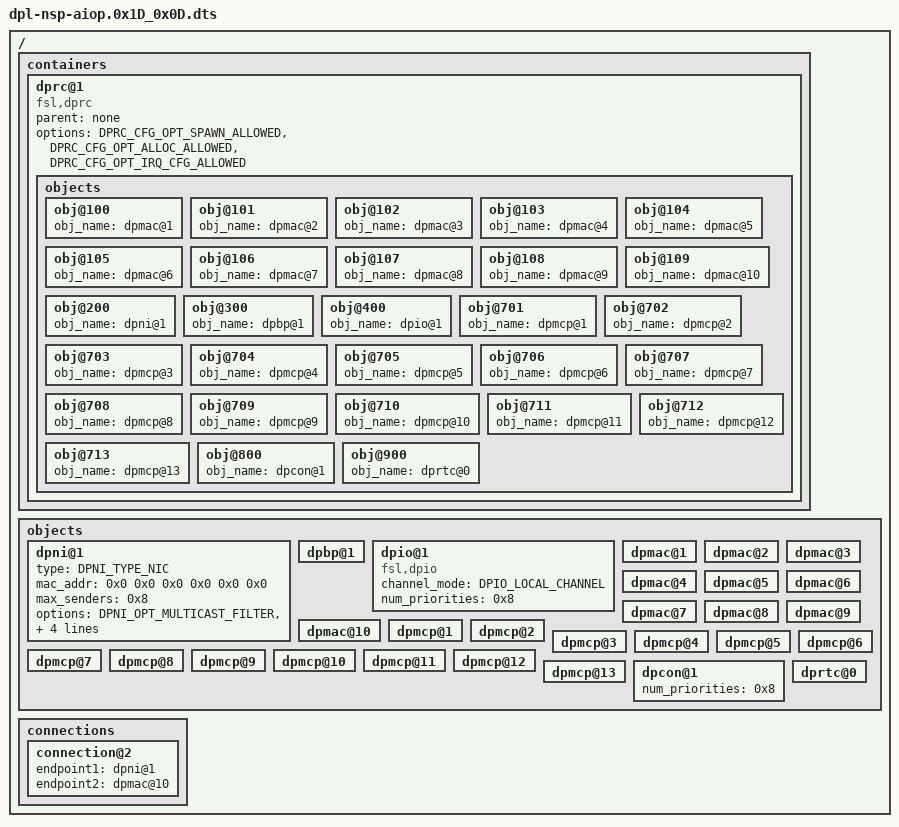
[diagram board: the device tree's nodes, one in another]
/*
 * Copyright 2017 NXP
 *
 * Redistribution and use in source and binary forms, with or without
 * modification, are permitted provided that the following conditions are met:
 *   * Redistributions of source code must retain the above copyright
 *     notice, this list of conditions and the following disclaimer.
 *   * Redistributions in binary form must reproduce the above copyright
 *     notice, this list of conditions and the following disclaimer in the
 *     documentation and/or other materials provided with the distribution.
 *   * Neither the name of the above-listed copyright holders nor the
 *     names of any contributors may be used to endorse or promote products
 *     derived from this software without specific prior written permission.
 *
 * THIS SOFTWARE IS PROVIDED BY THE COPYRIGHT HOLDERS AND CONTRIBUTORS "AS IS"
 * AND ANY EXPRESS OR IMPLIED WARRANTIES, INCLUDING, BUT NOT LIMITED TO, THE
 * IMPLIED WARRANTIES OF MERCHANTABILITY AND FITNESS FOR A PARTICULAR PURPOSE
 * ARE DISCLAIMED. IN NO EVENT SHALL THE COPYRIGHT HOLDERS OR CONTRIBUTORS BE
 * LIABLE FOR ANY DIRECT, INDIRECT, INCIDENTAL, SPECIAL, EXEMPLARY, OR
 * CONSEQUENTIAL DAMAGES (INCLUDING, BUT NOT LIMITED TO, PROCUREMENT OF
 * SUBSTITUTE GOODS OR SERVICES; LOSS OF USE, DATA, OR PROFITS; OR BUSINESS
 * INTERRUPTION) HOWEVER CAUSED AND ON ANY THEORY OF LIABILITY, WHETHER IN
 * CONTRACT, STRICT LIABILITY, OR TORT (INCLUDING NEGLIGENCE OR OTHERWISE)
 * ARISING IN ANY WAY OUT OF THE USE OF THIS SOFTWARE, EVEN IF ADVISED OF THE
 * POSSIBILITY OF SUCH DAMAGE.
 */
/dts-v1/;
/ {

	containers {

		dprc@1 {
			compatible = "fsl,dprc";
			parent = "none";
			options = "DPRC_CFG_OPT_SPAWN_ALLOWED", "DPRC_CFG_OPT_ALLOC_ALLOWED", "DPRC_CFG_OPT_IRQ_CFG_ALLOWED";

			objects {

				obj@100 {
					obj_name = "dpmac@1";
				};

				obj@101 {
					obj_name = "dpmac@2";
				};

				obj@102 {
					obj_name = "dpmac@3";
				};

				obj@103 {
					obj_name = "dpmac@4";
				};

				obj@104 {
					obj_name = "dpmac@5";
				};

				obj@105 {
					obj_name = "dpmac@6";
				};

				obj@106 {
					obj_name = "dpmac@7";
				};

				obj@107 {
					obj_name = "dpmac@8";
				};

				obj@108 {
					obj_name = "dpmac@9";
				};

				obj@109 {
					obj_name = "dpmac@10";
				};

				obj@200 {
					obj_name = "dpni@1";
				};

				obj@300 {
					obj_name = "dpbp@1";
				};

				obj@400 {
					obj_name = "dpio@1";
				};

				obj@701 {
					obj_name = "dpmcp@1";
				};

				obj@702 {
					obj_name = "dpmcp@2";
				};

				obj@703 {
					obj_name = "dpmcp@3";
				};

				obj@704 {
					obj_name = "dpmcp@4";
				};

				obj@705 {
					obj_name = "dpmcp@5";
				};

				obj@706 {
					obj_name = "dpmcp@6";
				};

				obj@707 {
					obj_name = "dpmcp@7";
				};

				obj@708 {
					obj_name = "dpmcp@8";
				};

				obj@709 {
					obj_name = "dpmcp@9";
				};

				obj@710 {
					obj_name = "dpmcp@10";
				};

				obj@711 {
					obj_name = "dpmcp@11";
				};

				obj@712 {
					obj_name = "dpmcp@12";
				};

				obj@713 {
					obj_name = "dpmcp@13";
				};

				obj@800 {
					obj_name = "dpcon@1";
				};

				obj@900 {
					obj_name = "dprtc@0";
				};
			};
		};
	};

	objects {

		dpni@1 {
			type = "DPNI_TYPE_NIC";
			mac_addr = <0x0 0x0 0x0 0x0 0x0 0x0>;
			max_senders = <0x8>;
			options = "DPNI_OPT_MULTICAST_FILTER", "DPNI_OPT_UNICAST_FILTER";
			max_tcs = <0x1>;
			max_dist_per_tc = <0x0>;
			max_dist_key_size = <0x18>;
		};

		dpbp@1 {
		};

		dpio@1 {
			compatible = "fsl,dpio";
			channel_mode = "DPIO_LOCAL_CHANNEL";
			num_priorities = <0x8>;
		};

		dpmac@1 {
		};

		dpmac@2 {
		};

		dpmac@3 {
		};

		dpmac@4 {
		};

		dpmac@5 {
		};

		dpmac@6 {
		};

		dpmac@7 {
		};

		dpmac@8 {
		};

		dpmac@9 {
		};

		dpmac@10 {
		};

		dpmcp@1 {
		};

		dpmcp@2 {
		};

		dpmcp@3 {
		};

		dpmcp@4 {
		};

		dpmcp@5 {
		};

		dpmcp@6 {
		};

		dpmcp@7 {
		};

		dpmcp@8 {
		};

		dpmcp@9 {
		};

		dpmcp@10 {
		};

		dpmcp@11 {
		};

		dpmcp@12 {
		};

		dpmcp@13 {
		};

		dpcon@1 {
			num_priorities = <0x8>;
		};

		dprtc@0 {
		};
	};

	connections {

		connection@2 {
			endpoint1 = "dpni@1";
			endpoint2 = "dpmac@10";
		};
	};
};
